# WKUP_CTRL_MMR0_WKUP_CTRL_MMR0_DEVICE_MANAGEMENT_43050000h register map
Vendor: Texas Instruments
Peripheral module from a debugger description file (folder am62L).
Registers are 32-bit, read-write, reset 0x0 unless marked. A register's access mark holds for its fields unless they carry their own. Offsets are as the file gives them; lines under a group give offsets from that group; [hi:lo] are bit positions; {n}, {i} and the like mark numbered series; 'fields as' and 'values as' point back to an identical list; <NAME> marks a mode.

## WKUP_CTRL_MMR0_DEVICE_MANAGEMENT
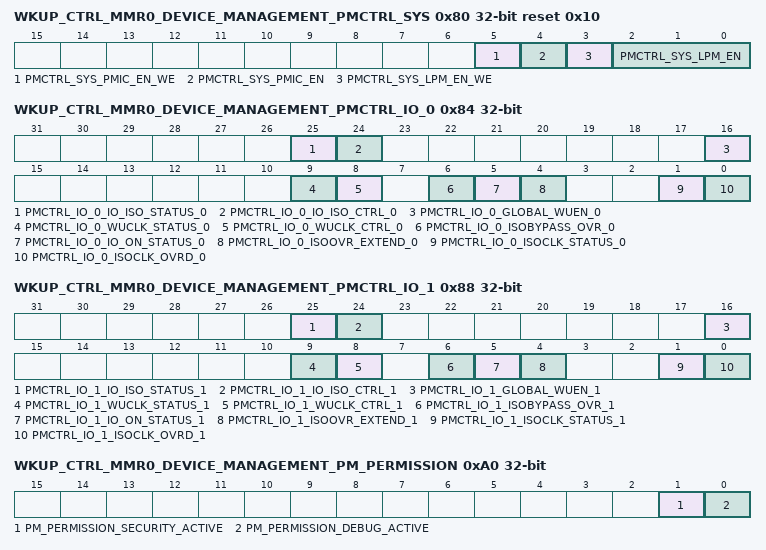
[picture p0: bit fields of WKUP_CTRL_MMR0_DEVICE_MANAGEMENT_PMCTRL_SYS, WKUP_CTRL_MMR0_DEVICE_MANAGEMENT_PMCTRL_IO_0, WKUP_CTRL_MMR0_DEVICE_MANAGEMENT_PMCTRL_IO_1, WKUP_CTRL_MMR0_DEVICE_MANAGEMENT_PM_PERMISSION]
0x80 WKUP_CTRL_MMR0_DEVICE_MANAGEMENT_PMCTRL_SYS reset 0x10 — This register determines how PMIC_LPM_EN_OUT is controlled, by Deep Sleep logic or directly by MMR control.
  [5] PMCTRL_SYS_PMIC_EN_WE — Unused Field - Value is Don't Care Reset Source: mod_g_rst_n
  [4] PMCTRL_SYS_PMIC_EN — Controls state of PMIC_LPM_EN_OUT when LPM_EN[2:0] is 000 Reset Source: mod_g_rst_n
  [3] PMCTRL_SYS_LPM_EN_WE — Unused Field - Value is Don't Care Reset Source: mod_g_rst_n
  [2:0] PMCTRL_SYS_LPM_EN — Controls whether PMIC_LPM_EN_OUT is driven by the pmic_en bit, or by deep sleep logic. Reset Source: mod_g_rst_n
0x84 WKUP_CTRL_MMR0_DEVICE_MANAGEMENT_PMCTRL_IO_0 access per field — This MMR controls the IO Daisy Chain 0
  [25] PMCTRL_IO_0_IO_ISO_STATUS_0 ro — IO ISO Status. Read 0: IO isolation not active. Read 1: IO isolation active.Reflects value of DM input port io_isoack coming back fromIO pad ring. Reset Source: mod_g_rst_n
  [24] PMCTRL_IO_0_IO_ISO_CTRL_0 rw — IO ISO control. Writing this bit to 1 will kick off IO isolation. Reset Source: mod_g_rst_n
  [16] PMCTRL_IO_0_GLOBAL_WUEN_0 rw — Global IO wakeup activate. This is a gating condition to allindividual IO WUEN coming from control module. Gating isdone in the Spinner logic. 0:All individual IO WUEN are gatedin the Spinner logic (override to 0). 1: All individual IO WUENfrom control module are going to Ios.Map to DM input port io_globalwkupen Reset Source: mod_g_rst_n
  [9] PMCTRL_IO_0_WUCLK_STATUS_0 ro — Reflects value of input port io_wuclkack coming backfrom IO pad ring. Reset Source: mod_g_rst_n
  [8] PMCTRL_IO_0_WUCLK_CTRL_0 rw — Direct control on WUCLKIN signal to IO pad ring.0:WUCLKINsignal is driven to 0.IO wakeup daisy chain is functional as wellas IO whose wakeup feature is activated. 1:WUCLKIN signal is driven to 1. IO wakeup daisy chain is reset and is latching current pad states and WUEN inputs. Reset Source: mod_g_rst_n
  [6] PMCTRL_IO_0_ISOBYPASS_OVR_0 rw — This MMR bit drives directly output port io_isobypassundefined. Reset Source: mod_g_rst_n
  [5] PMCTRL_IO_0_IO_ON_STATUS_0 ro — Gives the functional status of the IO ring. Read 0: Part or all ofthe Ios are not in the ON state that is are in isolation state.Read 1: All Ios are in the ON state.io_on_status = assign 1 if (io_iso == 0 & io_isoack==0 &io_iso_clk == 0 & io_isoclk_ack = 0 ) else 0; Reset Source: mod_g_rst_n
  [4] PMCTRL_IO_0_ISOOVR_EXTEND_0 rw — This drives the SOC chain ISO-OVERRIDE global control.This bit drives directly the output port io_isoovrundefined. Atthe SOC level it is used to activate when 1 or gate-off when 0,the individual ISOOR for each IO. This operates as a globalactivate/disable for the individual IOs.Control for IO isolation extension.'0' IO isolation is not extended. Transition happens as soon asautomatic restore is completed.'1' IO isolation is extended. The IOs whose ISOOVR bits havebeen individually set in their PADCFG MMRs will all get its IOisolation extended beyond the point when the initial IO daisychain isolation is released. Reset Source: mod_g_rst_n
  [1] PMCTRL_IO_0_ISOCLK_STATUS_0 ro — Reflects value of input port io_isoclkack coming backfrom IO pad ring. Reset Source: mod_g_rst_n
  [0] PMCTRL_IO_0_ISOCLK_OVRD_0 rw — Override control on ISOCLKIN signal to IO pad ring.When not overridden this signal is controlled by hardware only.0 ISOCLKIN signal is not override.1 ISOCLKIN signal is overridden to active value ('1'). Reset Source: mod_g_rst_n
0x88 WKUP_CTRL_MMR0_DEVICE_MANAGEMENT_PMCTRL_IO_1 access per field — This MMR controls the IO Daisy Chain 1
  [25] PMCTRL_IO_1_IO_ISO_STATUS_1 ro — IO ISO Status. Read 0: IO isolation not active. Read 1: IO isolation active.Reflects value of DM input port io_isoack coming back fromIO pad ring. Reset Source: mod_g_rst_n
  [24] PMCTRL_IO_1_IO_ISO_CTRL_1 rw — IO ISO control. Writing this bit to 1 will kick off IO isolation. Reset Source: mod_g_rst_n
  [16] PMCTRL_IO_1_GLOBAL_WUEN_1 rw — Global IO wakeup activate. This is a gating condition to allindividual IO WUEN coming from control module. Gating isdone in the Spinner logic. 0:All individual IO WUEN are gatedin the Spinner logic (override to 0). 1: All individual IO WUENfrom control module are going to Ios.Map to DM input port io_globalwkupen Reset Source: mod_g_rst_n
  [9] PMCTRL_IO_1_WUCLK_STATUS_1 ro — Reflects value of input port io_wuclkack coming backfrom IO pad ring. Reset Source: mod_g_rst_n
  [8] PMCTRL_IO_1_WUCLK_CTRL_1 rw — Direct control on WUCLKIN signal to IO pad ring.0:WUCLKINsignal is driven to 0.IO wakeup daisy chain is functional as wellas IO whose wakeup feature is activated. 1:WUCLKIN signal is driven to 1. IO wakeup daisy chain is reset and is latching current pad states and WUEN inputs. Reset Source: mod_g_rst_n
  [6] PMCTRL_IO_1_ISOBYPASS_OVR_1 rw — This MMR bit drives directly output port io_isobypassundefined. Reset Source: mod_g_rst_n
  [5] PMCTRL_IO_1_IO_ON_STATUS_1 ro — Gives the functional status of the IO ring. Read 0: Part or all ofthe Ios are not in the ON state that is are in isolation state.Read 1: All Ios are in the ON state.io_on_status = assign 1 if (io_iso == 0 & io_isoack==0 &io_iso_clk == 0 & io_isoclk_ack = 0 ) else 0; Reset Source: mod_g_rst_n
  [4] PMCTRL_IO_1_ISOOVR_EXTEND_1 rw — This drives the SOC chain ISO-OVERRIDE global control.This bit drives directly the output port io_isoovrundefined. Atthe SOC level it is used to activate when 1 or gate-off when 0,the individual ISOOR for each IO. This operates as a globalactivate/disable for the individual IOs.Control for IO isolation extension.'0' IO isolation is not extended. Transition happens as soon asautomatic restore is completed.'1' IO isolation is extended. The IOs whose ISOOVR bits havebeen individually set in their PADCFG MMRs will all get its IOisolation extended beyond the point when the initial IO daisychain isolation is released. Reset Source: mod_g_rst_n
  [1] PMCTRL_IO_1_ISOCLK_STATUS_1 ro — Reflects value of input port io_isoclkack coming backfrom IO pad ring. Reset Source: mod_g_rst_n
  [0] PMCTRL_IO_1_ISOCLK_OVRD_1 rw — Override control on ISOCLKIN signal to IO pad ring.When not overridden this signal is controlled by hardware only.0 ISOCLKIN signal is not override.1 ISOCLKIN signal is overridden to active value ('1'). Reset Source: mod_g_rst_n
0x90 WKUP_CTRL_MMR0_DEVICE_MANAGEMENT_PMCTRL_MOSC — This MMR controls the behavior of the oscillator during Deep Sleep entry.
  [31] PMCTRL_MOSC_OSC_CG_ON_WFI — To clock gate the main HFOSC, set this bit then enters the WFI state at which time the HFOSC will be gated. 0 INACTIVE1 ACTIVE
0x98 WKUP_CTRL_MMR0_DEVICE_MANAGEMENT_PM_MISC_STATUS ro — Reflects the progress of the request to clock-gate HFOSCvia MMR PMCTRL_MOSCundefined.
  [1:0] PM_MISC_STATUS_OSC_CG_STAT — HFOSC Clock Gating State 0 HFOSC_OFF3 HFOSC_ON
0xA0 WKUP_CTRL_MMR0_DEVICE_MANAGEMENT_PM_PERMISSION ro — This register (read only) reflects the status of different sources that may block or delay Deepsleep entry.
  [1] PM_PERMISSION_SECURITY_ACTIVE — Read Only - Reads return the value of SMS security active. When 1, indicates that SMS is blocking deep sleep entry. 0 DS_ALLOW1 DS_BLOCK
  [0] PM_PERMISSION_DEBUG_ACTIVE — Read Only - Returns a 1 when Debug is blocking deep sleep entry. 0 DS_ALLOW1 DS_BLOCK
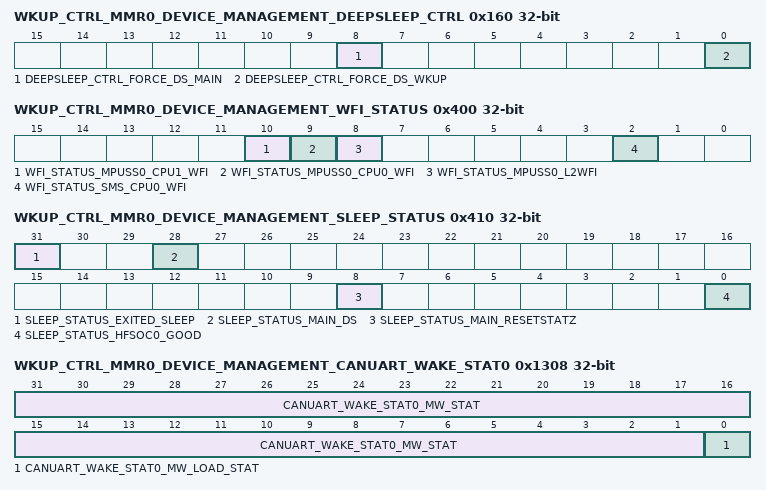
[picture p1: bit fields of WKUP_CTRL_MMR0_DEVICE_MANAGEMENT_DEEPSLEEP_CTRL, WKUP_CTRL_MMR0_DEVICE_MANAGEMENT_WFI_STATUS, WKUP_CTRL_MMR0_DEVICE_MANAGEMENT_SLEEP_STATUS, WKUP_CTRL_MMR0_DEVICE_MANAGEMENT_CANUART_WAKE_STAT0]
0x160 WKUP_CTRL_MMR0_DEVICE_MANAGEMENT_DEEPSLEEP_CTRL — Used to control IO deepsleep operation. Either this MMR or PMCTRL_IO_GLB (or both) may be used to force IOs into Deepsleep.
  [8] DEEPSLEEP_CTRL_FORCE_DS_MAIN — Force all MAIN IOs into deepsleep mode when set 0 IO_ACTIVE1 IO_DEEPSLEEP
  [0] DEEPSLEEP_CTRL_FORCE_DS_WKUP — Force all WKUP IOs into deepsleep mode when set 0 IO_ACTIVE1 IO_DEEPSLEEP
0x400 WKUP_CTRL_MMR0_DEVICE_MANAGEMENT_WFI_STATUS ro — Allows inspection of WFI Status of all CPU Cores
  [10] WFI_STATUS_MPUSS0_CPU1_WFI — WFI status of MPUSS0 CPU1 (only valid when CPU is out of reset) 0 UNKNOWN1 WFI_ACTIVE
  [9] WFI_STATUS_MPUSS0_CPU0_WFI — WFI status of MPUSS0 CPU0 (only valid when CPU is out of reset) 0 UNKNOWN1 WFI_ACTIVE
  [8] WFI_STATUS_MPUSS0_L2WFI — WFI status of MPUSS0 L2 (only valid when Cluster is out of reset) 0 UNKNOWN1 WFI_ACTIVE
  [2] WFI_STATUS_SMS_CPU0_WFI — WFI status of SMS Cortex M4F0 (only valid when CPU is out of reset) 0 UNKNOWN1 WFI_ACTIVE
0x410 WKUP_CTRL_MMR0_DEVICE_MANAGEMENT_SLEEP_STATUS access not given — Status Bits associated with Enter/Exit of Deep Sleep
  [31] SLEEP_STATUS_EXITED_SLEEP — Captures disable/gating of HFOSC. Use after WFI to determine whether HFOSC clocks were actually stopped, or if a new pending event prevented the HFOSC disable. 0 OTHER1 SLEEP_EXIT (access R/W1TC)
  [28] SLEEP_STATUS_MAIN_DS — Captures DS_MAIN por_pdoff assertion, so that after deepsleep exit software can differentiate between a regular power on reset and a main power on reset due to deepsleep exit. Write 1 to Clear this bit. 0 OTHER1 DS_EXIT (access R/W1TC)
  [8] SLEEP_STATUS_MAIN_RESETSTATZ ro — Reflects the status of the main domain reset (active low) 0 ASSERTED1 DEASSERTED
  [0] SLEEP_STATUS_HFSOC0_GOOD ro — Reserved Reset Source: mod_g_rst_n
0x500 WKUP_CTRL_MMR0_DEVICE_MANAGEMENT_DS_MAGIC_WORD — Deep Sleep State/Status MMR
  [31:0] DS_MAGIC_WORD_DS_MAGIC_WORD — Magic Word Indicating State of Deep Sleep Reset Source: chip1_rst_n
0x1000 WKUP_CTRL_MMR0_DEVICE_MANAGEMENT_WWD0_CTRL — Main RTI/WWDT0 Control of Suspend For Use During Low Power Entry/Exit
  [3:0] WWD0_CTRL_WWD_STOP — Controls Suspend Operation to the MAIN RTI/WWD0. This field must be programmed to 0xA to suspend the watchdog/rti. Other values behave as 0x0 Reset Source: mod_g_rst_n
0x1004 WKUP_CTRL_MMR0_DEVICE_MANAGEMENT_WWD1_CTRL — Main RTI/WWDT1 Control of Suspend For Use During Low Power Entry/Exit
  [3:0] WWD1_CTRL_WWD_STOP — Controls Suspend Operation to the MAIN RTI/WWD1. This field must be programmed to 0xA to suspend the watchdog/rti. Other values behave as 0x0 Reset Source: mod_g_rst_n
0x1308 WKUP_CTRL_MMR0_DEVICE_MANAGEMENT_CANUART_WAKE_STAT0 ro — Provides the status of CANUART_WAKE control bits.These bits come from the daisy-chain wakeup logic and maintain their value across core powerdown if isolation is activated.
  [31:1] CANUART_WAKE_STAT0_MW_STAT — CANUART magic word statusIndicates the latched value of the mw field. Reset Source: mod_por_rst_n
  [0] CANUART_WAKE_STAT0_MW_LOAD_STAT — Magic word load status.Indicates the latched value of the mw_load_en bit Reset Source: mod_por_rst_n
0x130C WKUP_CTRL_MMR0_DEVICE_MANAGEMENT_CANUART_WAKE_STAT1 ro — Provides CANUART IO isolation status.These bits come from the daisy-chain wakeup logic and maintain their value across core powerdown if isolation is activated
  [0] CANUART_WAKE_STAT1_CANUART_IO_MODE — Indicates if CANUART IO wakeup mode is activated. 0 INACTIVE1 ACTIVATED
0x1310 WKUP_CTRL_MMR0_DEVICE_MANAGEMENT_CANUART_WAKE_OFF_MODE
  [31:0] CANUART_WAKE_OFF_MODE_MW — Off Mode Magic Word.Setting this field to 0xXX555555 is part of the IO + DDR Off Mode Sequence.When this magic word is matched, then loading DDR32SS_PMCTRL.ddr_retention[3:0] into the IO+DDR retention domain is possible.When the magic word is set to any other value, updating DDR32SS_PMCTRL.ddr_retention[3:0] is blocked. The upper 8 bits of this MMR are available for software to use for its own purpose. Reset Source: mod_por_rst_n
0x1318 WKUP_CTRL_MMR0_DEVICE_MANAGEMENT_CANUART_WAKE_OFF_MODE_STAT ro
  [31:0] CANUART_WAKE_OFF_MODE_STAT_MW — returned magic word Reset Source: mod_por_rst_n
0x2000 WKUP_CTRL_MMR0_DEVICE_MANAGEMENT_PMCTRL_MOSC_STARTUP reset 0xBC00
  [19:0] PMCTRL_MOSC_STARTUP_SETUP_TIME — Number of HFOSC clock cycles before HFOSC clock is ungated to the SOC (allows the HFOSC time to stabilize after starting up, before the SOC is clocked). Reset Source: mod_g_rst_n
0x2100 WKUP_CTRL_MMR0_DEVICE_MANAGEMENT_HFOSC0_STAT ro — Status of HFOSC Power Down
  [0] HFOSC0_STAT_DS_ON_WFI_STAT — Reflects the status of Request to Disable HFOSC0 on WFI. (DeepSleep Entry) 0 NO_DEEPSLEEP_REQUEST1 DEEPSLEEP_REQUEST
0x3000 WKUP_CTRL_MMR0_DEVICE_MANAGEMENT_CANUART_WAKE_RESUME_KEY_j
  [31:0] KEYVAL — key value Reset Source: mod_por_rst_n
0x3100 WKUP_CTRL_MMR0_DEVICE_MANAGEMENT_CANUART_WAKE_RESUME_KEY_STAT_j ro
  [31:0] KEYVAL — returned key value Reset Source: mod_por_rst_n
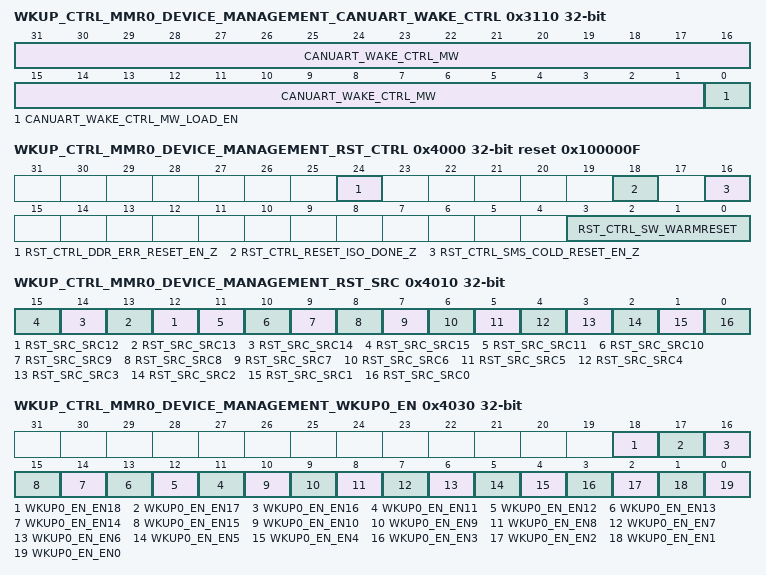
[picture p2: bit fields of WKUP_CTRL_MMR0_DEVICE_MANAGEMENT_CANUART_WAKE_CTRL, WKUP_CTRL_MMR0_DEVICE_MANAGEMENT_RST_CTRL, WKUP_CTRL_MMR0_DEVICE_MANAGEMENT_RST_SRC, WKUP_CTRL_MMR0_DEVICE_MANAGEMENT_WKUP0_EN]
0x3110 WKUP_CTRL_MMR0_DEVICE_MANAGEMENT_CANUART_WAKE_CTRL — Controls the operation of IO wakeup on the CANUART pins.
  [31:1] CANUART_WAKE_CTRL_MW — CANUART IO magic word. When these 31 bits are written 0x2AAAAAAA and mw_load_en is toggled, then the CANUART IO Isolation mode is entered.Any other values will prevent entry. (Note: the entire 32 bit register including the mw_load is written 0x55555555 then 0x55555554). 0 DEACTIVATE14316 ACTIVATE55765
  [0] CANUART_WAKE_CTRL_MW_LOAD_EN — Magic word load activateSetting this bit loads and locks the mw field for CANUART IO isolation. If the mw field matches ACTIVATE, CANUART IO Isolation is initiated. 0 UNLOCK1 LOCK_AND_LOAD
0x4000 WKUP_CTRL_MMR0_DEVICE_MANAGEMENT_RST_CTRL reset 0x100000F — Controls Reset Assertion and Propogation
  [24] RST_CTRL_DDR_ERR_RESET_EN_Z — Deactivate Reset by DDRSS Error 0 PROPOGATE1 BLOCK
  [18] RST_CTRL_RESET_ISO_DONE_Z — Blocks Warm Reset. 0 PROPOGATE1 BLOCK
  [16] RST_CTRL_SMS_COLD_RESET_EN_Z — Deactivate Reset by SMS 0 PROPOGATE1 BLOCK
  [3:0] RST_CTRL_SW_WARMRESET — Causes MAIN Domain Warm Reset. This is a fault tolerant bitfield. Automatically resets to 4'b1111 after write. 6 FORCE_RESET15 INACTIVE
0x4010 WKUP_CTRL_MMR0_DEVICE_MANAGEMENT_RST_SRC access not given — Captures Reason for Warm and Main Domain Power On Resets - Write 1 to Clear
  [n] RST_SRC_SRC{n} (n=12..15) — reserved 0 UNKNOWN1 DETECTED (access R/W1TC)
  [11] RST_SRC_SRC11 — DDRSS Timeout Reset 0 UNKNOWN1 DETECTED (access R/W1TC)
  [10] RST_SRC_SRC10 — Debug Subsystem Initiated Reset 0 UNKNOWN1 DETECTED (access R/W1TC)
  [9] RST_SRC_SRC9 — Thermal Reset 0 UNKNOWN1 DETECTED (access R/W1TC)
  [8] RST_SRC_SRC8 — reserved 0 UNKNOWN1 DETECTED (access R/W1TC)
  [7] RST_SRC_SRC7 — reserved 0 UNKNOWN1 DETECTED (access R/W1TC)
  [6] RST_SRC_SRC6 — reserved 0 UNKNOWN1 DETECTED (access R/W1TC)
  [5] RST_SRC_SRC5 — Reset Caused by MPU Watchdog 1 0 UNKNOWN1 DETECTED (access R/W1TC)
  [4] RST_SRC_SRC4 — Reset Caused by MPU Watchdog 0 0 UNKNOWN1 DETECTED (access R/W1TC)
  [3] RST_SRC_SRC3 — Reset Caused by SMS (Warm Reset) 0 UNKNOWN1 DETECTED (access R/W1TC)
  [2] RST_SRC_SRC2 — Reset Caused by SMS (Cold Reset) 0 UNKNOWN1 DETECTED (access R/W1TC)
  [1] RST_SRC_SRC1 — Reset caused by SW_WARMRESET Request 1 DETECTED (access R/W1TC)
  [0] RST_SRC_SRC0 — Reset caused by Device Warm Reset RESETz pin assertion 1 DETECTED (access R/W1TC)
0x4030 WKUP_CTRL_MMR0_DEVICE_MANAGEMENT_WKUP0_EN — This register enables SOC events for Wakeup from Deep Sleep
  [18] WKUP0_EN_EN18 — Enable Source 18 Wakeup: RTC IO Wakeup Event 0 NOT_ENABLED1 ENABLED
  [17] WKUP0_EN_EN17 — Enable Source 17 Wakeup: WKUP_IO_DAISY_CHAIN 0 NOT_ENABLED1 ENABLED
  [16] WKUP0_EN_EN16 — Enable Source 16 Wakeup: MAIN_IO_DAISY_CHAIN 0 NOT_ENABLED1 ENABLED
  [n] WKUP0_EN_EN{n} (n=11..15) — Enable Source {n} Wakeup: Reserved 0 NOT_ENABLED1 ENABLED
  [10] WKUP0_EN_EN10 — Enable Source 10 Wakeup: USB1_IN_BAND 0 NOT_ENABLED1 ENABLED
  [9] WKUP0_EN_EN9 — Enable Source 9 Wakeup: USB0_IN_BAND 0 NOT_ENABLED1 ENABLED
  [8] WKUP0_EN_EN8 — Enable Source 11 Wakeup: Reserved 0 NOT_ENABLED1 ENABLED
  [7] WKUP0_EN_EN7 — Enable Source 7 Wakeup: WKUP_RTC0 0 NOT_ENABLED1 ENABLED
  [6] WKUP0_EN_EN6 — Enable Source 6 Wakeup: WKUP_TIMER1 0 NOT_ENABLED1 ENABLED
  [5] WKUP0_EN_EN5 — Enable Source 5 Wakeup: WKUP_TIMER0 0 NOT_ENABLED1 ENABLED
  [4] WKUP0_EN_EN4 — Enable Source 4 Wakeup: Reserved 1 ENABLED0xNaN undefined
  [3] WKUP0_EN_EN3 — Enable Source 3 Wakeup: Debug 0 NOT_ENABLED1 ENABLED
  [2] WKUP0_EN_EN2 — Enable Source 2 Wakeup: WKUP_GPIO0 0 NOT_ENABLED1 ENABLED
  [1] WKUP0_EN_EN1 — Enable Source 1 Wakeup: WKUP_USART0 0 NOT_ENABLED1 ENABLED
  [0] WKUP0_EN_EN0 — Enable Source 0 Wakeup: WKUP_I2C0 0 NOT_ENABLED1 ENABLED
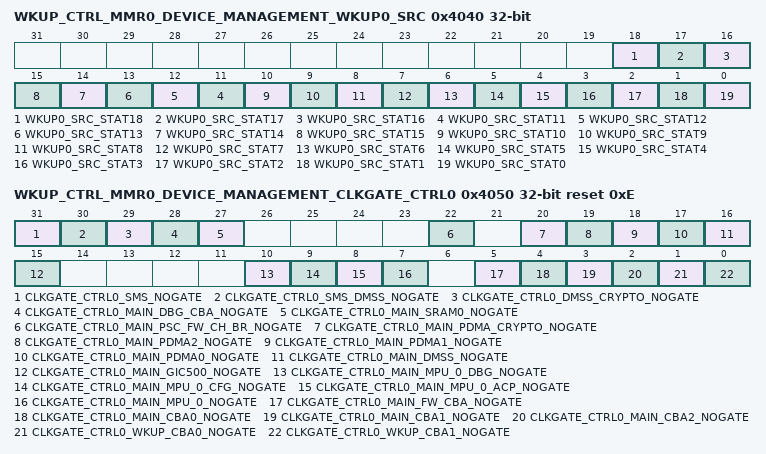
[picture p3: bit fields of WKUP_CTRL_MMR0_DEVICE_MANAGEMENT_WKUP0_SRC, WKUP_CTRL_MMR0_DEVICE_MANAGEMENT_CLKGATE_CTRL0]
0x4040 WKUP_CTRL_MMR0_DEVICE_MANAGEMENT_WKUP0_SRC access not given — This register captures requests for Wakeup from Deep Sleep
  [18] WKUP0_SRC_STAT18 — Status of Source 18 Wakeup: RTC IO Wakeup Event 0 NOT_DETECTED1 DETECTED (access R/W1TC)
  [17] WKUP0_SRC_STAT17 — Status of Source 17 Wakeup: WKUP_IO_DAISY_CHAIN 0 NOT_DETECTED1 DETECTED (access R/W1TC)
  [16] WKUP0_SRC_STAT16 — Status of Source 16 Wakeup: MAIN_IO_DAISY_CHAIN 0 NOT_DETECTED1 DETECTED (access R/W1TC)
  [n] WKUP0_SRC_STAT{n} (n=11..15) — Status of Source {n} Wakeup: Reserved 0 NOT_DETECTED1 DETECTED (access R/W1TC)
  [10] WKUP0_SRC_STAT10 — Status of Source 10 Wakeup: USB1_IN_BAND 0 NOT_DETECTED1 DETECTED (access R/W1TC)
  [9] WKUP0_SRC_STAT9 — Status of Source 9 Wakeup: USB0_IN_BAND 0 NOT_DETECTED1 DETECTED (access R/W1TC)
  [8] WKUP0_SRC_STAT8 — Status of Source 11 Wakeup: Reserved 0 NOT_DETECTED1 DETECTED (access R/W1TC)
  [7] WKUP0_SRC_STAT7 — Status of Source 7 Wakeup: WKUP_RTC0 0 NOT_DETECTED1 DETECTED (access R/W1TC)
  [6] WKUP0_SRC_STAT6 — Status of Source 6 Wakeup: WKUP_TIMER1 0 NOT_DETECTED1 DETECTED (access R/W1TC)
  [5] WKUP0_SRC_STAT5 — Status of Source 5 Wakeup: WKUP_TIMER0 0 NOT_DETECTED1 DETECTED (access R/W1TC)
  [4] WKUP0_SRC_STAT4 — Status of Source 4 Wakeup: Reserved 0 NOT_DETECTED1 DETECTED (access R/W1TC)
  [3] WKUP0_SRC_STAT3 — Status of Source 3 Wakeup: Debug 0 NOT_DETECTED1 DETECTED (access R/W1TC)
  [2] WKUP0_SRC_STAT2 — Status of Source 2 Wakeup: WKUP_GPIO0 0 NOT_DETECTED1 DETECTED (access R/W1TC)
  [1] WKUP0_SRC_STAT1 — Status of Source 1 Wakeup: WKUP_USART0 0 NOT_DETECTED1 DETECTED (access R/W1TC)
  [0] WKUP0_SRC_STAT0 — Status of Source 0 Wakeup: WKUP_I2C0 0 NOT_DETECTED1 DETECTED (access R/W1TC)
0x4050 WKUP_CTRL_MMR0_DEVICE_MANAGEMENT_CLKGATE_CTRL0 reset 0xE — Controls the power clock gating feature of WKUP domain modules and busses
  [31] CLKGATE_CTRL0_SMS_NOGATE — SMS auto clock gate on idle deactivate. 0 ACTIVE1 INACTIVE
  [30] CLKGATE_CTRL0_SMS_DMSS_NOGATE — SMS to DMSS auto clock gate on idle deactivate. 0 ACTIVE1 INACTIVE
  [29] CLKGATE_CTRL0_DMSS_CRYPTO_NOGATE — DMSS_CRYPTO auto clock gate on idle deactivate. 0 ACTIVE1 INACTIVE
  [28] CLKGATE_CTRL0_MAIN_DBG_CBA_NOGATE — MAIN domain Debug CBASS auto clock gate on idle deactivate. 0 ACTIVE1 INACTIVE
  [27] CLKGATE_CTRL0_MAIN_SRAM0_NOGATE — MAIN domain SRAM0 auto clock gate on idle deactivate 0 ACTIVE1 INACTIVE
  [22] CLKGATE_CTRL0_MAIN_PSC_FW_CH_BR_NOGATE — MAIN domain PSC firewall auto clock gate on idle deactivate 0 ACTIVE1 INACTIVE
  [20] CLKGATE_CTRL0_MAIN_PDMA_CRYPTO_NOGATE — MAIN domain PDMA Crypto auto clock gate on idle deactivate. 0 ACTIVE1 INACTIVE
  [19] CLKGATE_CTRL0_MAIN_PDMA2_NOGATE — MAIN domain PDMA2 auto clock gate on idle deactivate. 0 ACTIVE1 INACTIVE
  [18] CLKGATE_CTRL0_MAIN_PDMA1_NOGATE — MAIN domain PDMA1 auto clock gate on idle deactivate. 0 ACTIVE1 INACTIVE
  [17] CLKGATE_CTRL0_MAIN_PDMA0_NOGATE — MAIN domain PDMA0 auto clock gate on idle deactivate. 0 ACTIVE1 INACTIVE
  [16] CLKGATE_CTRL0_MAIN_DMSS_NOGATE — MAIN domain DMSS auto clock gate on idle deactivate. 0 ACTIVE1 INACTIVE
  [15] CLKGATE_CTRL0_MAIN_GIC500_NOGATE — MAIN MPUSS0 GIC500 auto clock gate on idle deactivate. 0 ACTIVE1 INACTIVE
  [10] CLKGATE_CTRL0_MAIN_MPU_0_DBG_NOGATE — MAIN MPUSS0 Debug Port auto clock gate on idle deactivate. 0 ACTIVE1 INACTIVE
  [9] CLKGATE_CTRL0_MAIN_MPU_0_CFG_NOGATE — MAIN MPUSS0 Configuration Port auto clock gate on idle deactivate. 0 ACTIVE1 INACTIVE
  [8] CLKGATE_CTRL0_MAIN_MPU_0_ACP_NOGATE — MAIN MPUSS0 ACP auto clock gate on idle deactivate. 0 ACTIVE1 INACTIVE
  [7] CLKGATE_CTRL0_MAIN_MPU_0_NOGATE — MAIN MPUSS0 auto clock gate on idle deactivate. 0 ACTIVE1 INACTIVE
  [5] CLKGATE_CTRL0_MAIN_FW_CBA_NOGATE — MAIN domain data bus auto clock gate on idle deactivate. 0 ACTIVE1 INACTIVE
  [4] CLKGATE_CTRL0_MAIN_CBA0_NOGATE — MAIN Domain CBA0 auto clock gate on idle deactivate 0 ACTIVE1 INACTIVE
  [3] CLKGATE_CTRL0_MAIN_CBA1_NOGATE — MAIN Domain CBA1 auto clock gate on idle deactivate 0 ACTIVE1 INACTIVE
  [2] CLKGATE_CTRL0_MAIN_CBA2_NOGATE — MAIN Domain CBA2 auto clock gate on idle deactivate 0 ACTIVE1 INACTIVE
  [1] CLKGATE_CTRL0_WKUP_CBA0_NOGATE — WKUP Domain CBA0 auto clock gate on idle deactivate 0 ACTIVE1 INACTIVE
  [0] CLKGATE_CTRL0_WKUP_CBA1_NOGATE — WKUP Domain CBA1 auto clock gate on idle deactivate 0 ACTIVE1 INACTIVE
